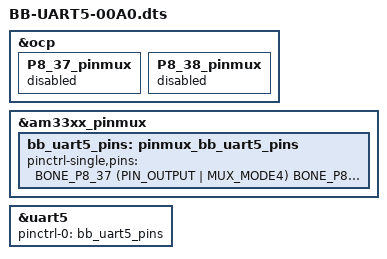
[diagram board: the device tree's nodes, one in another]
/*
 * Copyright (C) 2013 CircuitCo
 *
 * Virtual cape for UART5 on connector pins P9.37 P8.38
 *
 * This program is free software; you can redistribute it and/or modify
 * it under the terms of the GNU General Public License version 2 as
 * published by the Free Software Foundation.
 */

/dts-v1/;
/plugin/;

#include <dt-bindings/board/am335x-bbw-bbb-base.h>
#include <dt-bindings/pinctrl/am33xx.h>

/ {
	/*
	 * Free up the pins used by the cape from the pinmux helpers.
	 */
	fragment@0 {
		target = <&ocp>;
		__overlay__ {
			P8_37_pinmux { status = "disabled"; };	/* uart5_txd */
			P8_38_pinmux { status = "disabled"; };	/* uart5_rxd */
		};
	};

	fragment@1 {
		target = <&am33xx_pinmux>;
		__overlay__ {
			bb_uart5_pins: pinmux_bb_uart5_pins {
				pinctrl-single,pins = <
					BONE_P8_37 (PIN_OUTPUT | MUX_MODE4)	// lcd_data8.uart5_txd
					BONE_P8_38 (PIN_INPUT  | MUX_MODE4)	// lcd_data9.uart5_rxd
				>;
			};
		};
	};

	fragment@2 {
		target = <&uart5>;
		__overlay__ {
			status = "okay";
			pinctrl-names = "default";
			pinctrl-0 = <&bb_uart5_pins>;
		};
	};
};
